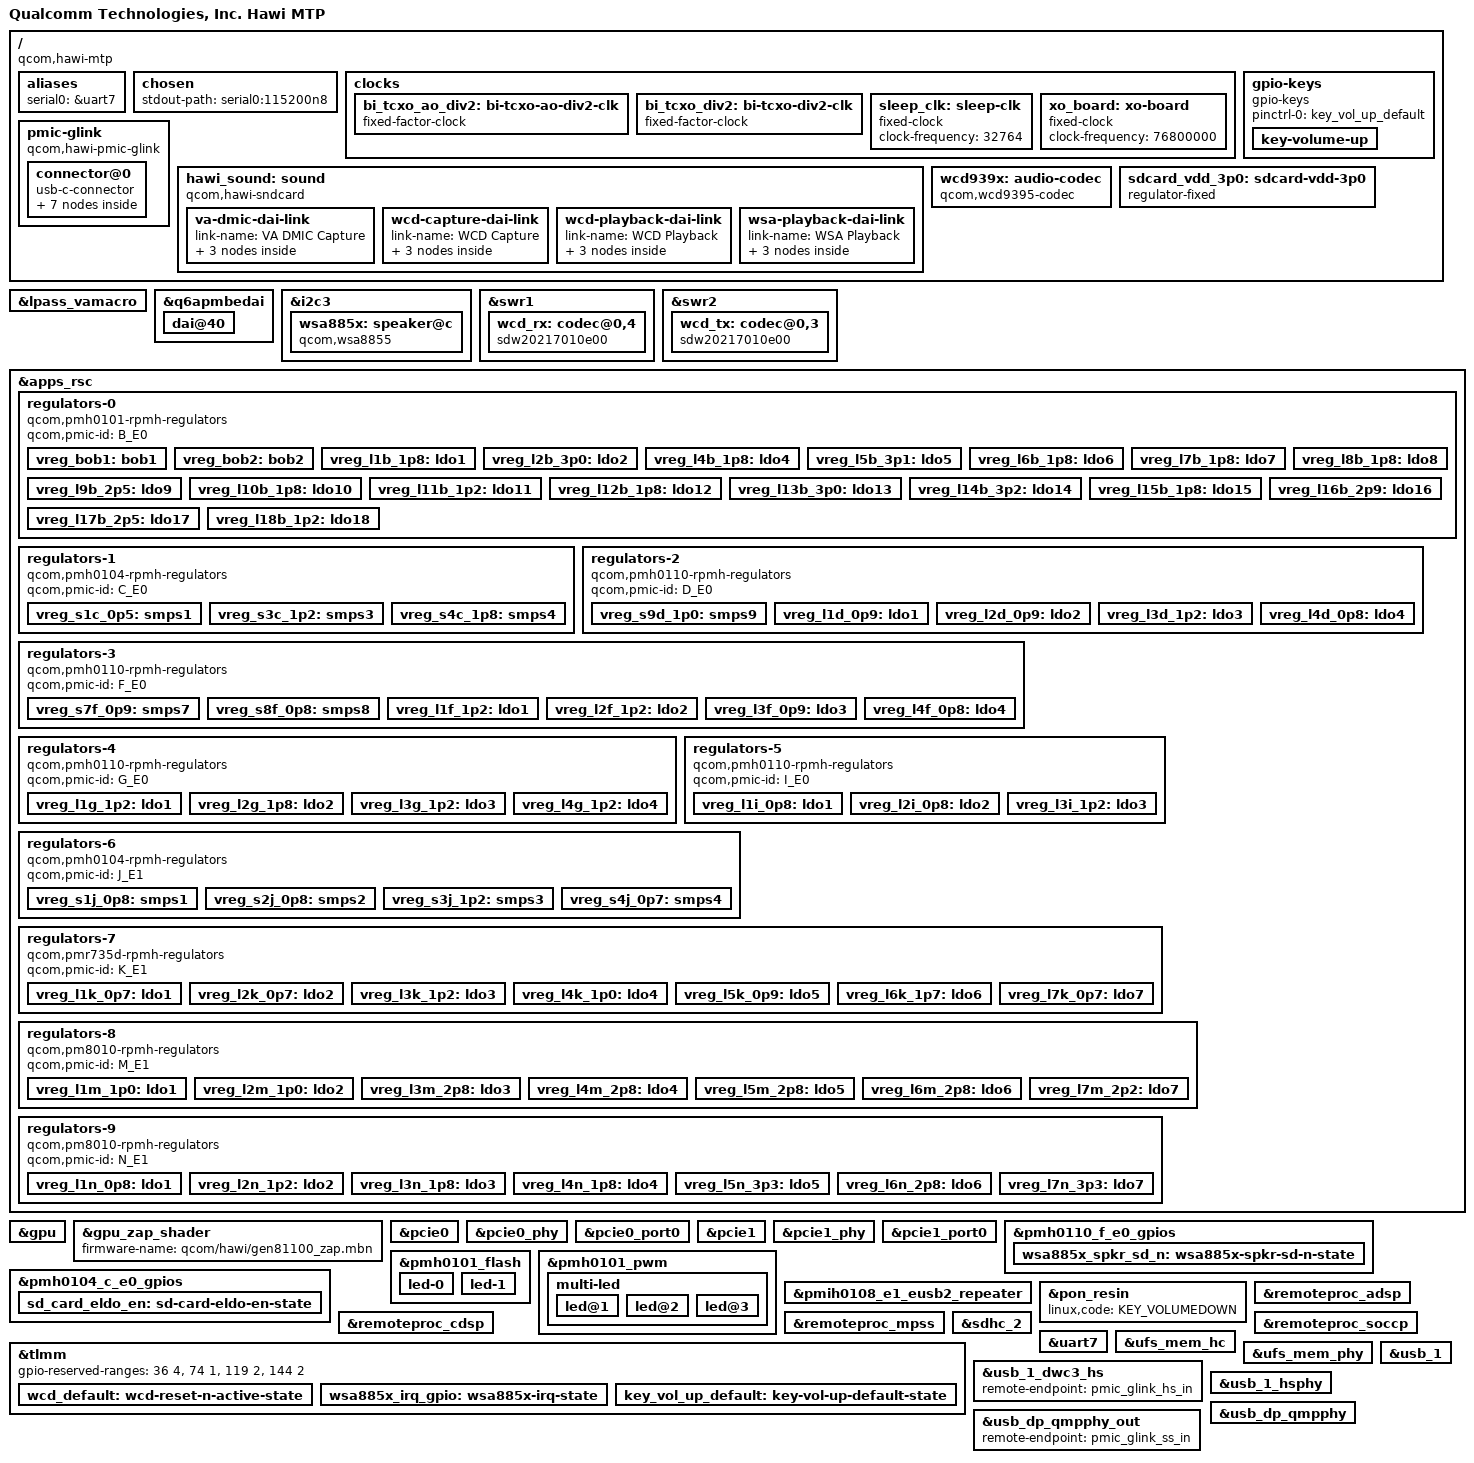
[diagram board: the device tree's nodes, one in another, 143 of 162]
// SPDX-License-Identifier: BSD-3-Clause
/*
 * Copyright (c) Qualcomm Technologies, Inc. and/or its subsidiaries.
 */

/dts-v1/;
#include <dt-bindings/gpio/gpio.h>
#include <dt-bindings/interrupt-controller/irq.h>
#include <dt-bindings/input/linux-event-codes.h>
#include <dt-bindings/leds/common.h>
#include <dt-bindings/pinctrl/qcom,pmic-gpio.h>
#include <dt-bindings/regulator/qcom,rpmh-regulator.h>
#include <dt-bindings/sound/qcom,q6dsp-lpass-ports.h>

#include "hawi.dtsi"

#include "pmd8028-kaanapali.dtsi"	/* SPMI1: SID-4 */
#include "pmh0101.dtsi"			/* SPMI0: SID-1 */
#include "pmh0104-hawi.dtsi"		/* SPMI0: SID-2 SPMI1: SID-9 */
#include "pmh0110-kaanapali.dtsi"	/* SPMI0: SID-3/5/6/8 */
#include "pmih0108-kaanapali.dtsi"	/* SPMI1: SID-7 */
#include "pmk8850.dtsi"			/* SPMI0: SID-0 */
#include "pmr735d-kaanapali.dtsi"	/* SPMI1: SID-A */
#include "pm8010-kaanapali.dtsi"	/* SPMI1: SID-C/D */

/ {
	model = "Qualcomm Technologies, Inc. Hawi MTP";
	compatible = "qcom,hawi-mtp", "qcom,hawi";
	chassis-type = "handset";

	aliases {
		serial0 = &uart7;
	};

	chosen {
		stdout-path = "serial0:115200n8";
	};

	clocks {
		bi_tcxo_ao_div2: bi-tcxo-ao-div2-clk {
			compatible = "fixed-factor-clock";
			#clock-cells = <0>;

			clocks = <&rpmhcc RPMH_CXO_CLK_A>;
			clock-mult = <1>;
			clock-div = <2>;
		};

		bi_tcxo_div2: bi-tcxo-div2-clk {
			compatible = "fixed-factor-clock";
			#clock-cells = <0>;

			clocks = <&rpmhcc RPMH_CXO_CLK>;
			clock-mult = <1>;
			clock-div = <2>;
		};

		sleep_clk: sleep-clk {
			compatible = "fixed-clock";
			clock-frequency = <32764>;
			#clock-cells = <0>;
		};

		xo_board: xo-board {
			compatible = "fixed-clock";
			clock-frequency = <76800000>;
			#clock-cells = <0>;
		};
	};

	gpio-keys {
		compatible = "gpio-keys";

		pinctrl-0 = <&key_vol_up_default>;
		pinctrl-names = "default";

		key-volume-up {
			label = "Volume Up";
			linux,code = <KEY_VOLUMEUP>;
			gpios = <&tlmm 101 GPIO_ACTIVE_LOW>;
			debounce-interval = <15>;
			linux,can-disable;
			wakeup-source;
		};
	};

	pmic-glink {
		compatible = "qcom,hawi-pmic-glink",
			     "qcom,kaanapali-pmic-glink",
			     "qcom,pmic-glink";
		#address-cells = <1>;
		#size-cells = <0>;

		connector@0 {
			compatible = "usb-c-connector";
			reg = <0>;

			power-role = "dual";
			data-role = "dual";

			ports {
				#address-cells = <1>;
				#size-cells = <0>;

				port@0 {
					reg = <0>;

					pmic_glink_hs_in: endpoint {
						remote-endpoint = <&usb_1_dwc3_hs>;
					};
				};

				port@1 {
					reg = <1>;

					pmic_glink_ss_in: endpoint {
						remote-endpoint = <&usb_dp_qmpphy_out>;
					};
				};

				port@2 {
					reg = <2>;

					pmic_glink_dp_out: endpoint {
						//remote-endpoint = <&usb_dp_qmpphy_dp_in>;
					};
				};
			};
		};
	};

	hawi_sound: sound {
		compatible = "qcom,hawi-sndcard", "qcom,sm8450-sndcard";
		model = "HAWI-MTP";

		audio-routing = "IN1_HPHL", "HPHL_OUT",
				"IN2_HPHR", "HPHR_OUT",
				"AMIC2", "MIC BIAS2",
				"VA DMIC0", "MIC BIAS1",
				"VA DMIC1", "MIC BIAS1",
				"VA DMIC2", "MIC BIAS3",
				"VA DMIC3", "MIC BIAS3",
				"TX SWR_INPUT", "ADC2_OUTPUT";

		pinctrl-names = "default", "sleep";
		pinctrl-0 = <&lpi_i2s1_active>;
		pinctrl-1 = <&lpi_i2s1_sleep>;

		va-dmic-dai-link {
			link-name = "VA DMIC Capture";

			codec {
				sound-dai = <&lpass_vamacro 0>;
			};

			cpu {
				sound-dai = <&q6apmbedai VA_CODEC_DMA_TX_0>;
			};

			platform {
				sound-dai = <&q6apm>;
			};
		};

		wcd-capture-dai-link {
			link-name = "WCD Capture";

			codec {
				sound-dai = <&wcd939x 1>, <&swr2 0>, <&lpass_txmacro 0>;
			};

			cpu {
				sound-dai = <&q6apmbedai TX_CODEC_DMA_TX_3>;
			};

			platform {
				sound-dai = <&q6apm>;
			};
		};

		wcd-playback-dai-link {
			link-name = "WCD Playback";

			codec {
				sound-dai = <&wcd939x 0>, <&swr1 0>, <&lpass_rxmacro 0>;
			};

			cpu {
				sound-dai = <&q6apmbedai RX_CODEC_DMA_RX_0>;
			};

			platform {
				sound-dai = <&q6apm>;
			};
		};

		wsa-playback-dai-link {
			link-name = "WSA Playback";

			codec {
				sound-dai = <&wsa885x>;
				dai-tdm-slot-num = <2>;
				dai-tdm-slot-width = <32>;
				dai-tdm-slot-rx-mask = <1 1>;
			};

			cpu {
				sound-dai = <&q6apmbedai AIF_TDM_RX_1>;
				dai-tdm-slot-num = <2>;
				dai-tdm-slot-width = <32>;
				dai-tdm-slot-rx-mask = <1 1>;
			};

			platform {
				sound-dai = <&q6apm>;
			};
		};
	};

	wcd939x: audio-codec {
		compatible = "qcom,wcd9395-codec", "qcom,wcd9390-codec";

		pinctrl-0 = <&wcd_default>;
		pinctrl-names = "default";

		qcom,mbhc-buttons-vthreshold-microvolt = <75000 150000 237000 500000
							 500000 500000 500000 500000>;
		qcom,mbhc-headphone-vthreshold-microvolt = <50000>;
		qcom,mbhc-headset-vthreshold-microvolt = <1700000>;
		qcom,micbias1-microvolt = <1800000>;
		qcom,micbias2-microvolt = <1800000>;
		qcom,micbias3-microvolt = <1800000>;
		qcom,micbias4-microvolt = <1800000>;
		qcom,rx-device = <&wcd_rx>;
		qcom,tx-device = <&wcd_tx>;

		reset-gpios = <&tlmm 161 GPIO_ACTIVE_LOW>;

		vdd-buck-supply = <&vreg_l15b_1p8>;
		vdd-io-supply = <&vreg_l15b_1p8>;
		vdd-mic-bias-supply = <&vreg_bob1>;
		vdd-px-supply = <&vreg_l3i_1p2>;
		vdd-rxtx-supply = <&vreg_l15b_1p8>;

		#sound-dai-cells = <1>;
	};

	sdcard_vdd_3p0: sdcard-vdd-3p0 {
		compatible = "regulator-fixed";

		regulator-name = "sdc-vdd123";
		regulator-min-microvolt = <3000000>;
		regulator-max-microvolt = <3000000>;
		regulator-enable-ramp-delay = <1500>;

		gpio = <&pmh0104_c_e0_gpios 5 GPIO_ACTIVE_HIGH>;
		enable-active-high;

		pinctrl-0 = <&sd_card_eldo_en>;
		pinctrl-names = "default";

		vin-supply = <&vreg_bob1>;
	};
};

&lpass_vamacro {
	pinctrl-0 = <&dmic01_default>, <&dmic23_default>;
	pinctrl-names = "default";

	vdd-micb-supply = <&vreg_l10b_1p8>;
	qcom,dmic-sample-rate = <4800000>;
};


&q6apmbedai {
	dai@40 {
		reg = <AIF_TDM_RX_1>;
		clocks = <&q6prmcc LPASS_CLK_ID_QAIF_IF1_IBIT
			  LPASS_CLK_ATTRIBUTE_COUPLE_NO>;
		clock-names = "bclk";
	};
};

&i2c3 {
	status = "okay";

	wsa885x: speaker@c {
		compatible = "qcom,wsa8855";
		reg = <0x0c>;

		interrupt-parent = <&tlmm>;
		interrupts = <77 IRQ_TYPE_EDGE_FALLING>;

		pinctrl-0 = <&wsa885x_spkr_sd_n &wsa885x_irq_gpio>;
		pinctrl-names = "default";

		powerdown-gpios = <&pmh0110_f_e0_gpios 11 GPIO_ACTIVE_LOW>;

		vdd-1p8-supply = <&vreg_l2g_1p8>;
		vdd-io-supply = <&vreg_l1g_1p2>;

		qcom,battery-config = "1s";

		#sound-dai-cells = <0>;

		status = "okay";
	};
};

&swr1 {
	status = "okay";
	wcd_rx: codec@0,4 {
		compatible = "sdw20217010e00";
		reg = <0 4>;

		qcom,rx-port-mapping = <1 2 3 4 5 9>;
	};
};

&swr2 {
	status = "okay";

	wcd_tx: codec@0,3 {
		compatible = "sdw20217010e00";
		reg = <0 3>;
		qcom,tx-port-mapping = <3 3 3 4>;
	};
};

&apps_rsc {
	regulators-0 {
		compatible = "qcom,pmh0101-rpmh-regulators";
		qcom,pmic-id = "B_E0";

		vreg_bob1: bob1 {
			regulator-name = "vreg_bob1";
			regulator-min-microvolt = <3008000>;
			regulator-max-microvolt = <4000000>;
			regulator-initial-mode = <RPMH_REGULATOR_MODE_HPM>;
		};

		vreg_bob2: bob2 {
			regulator-name = "vreg_bob2";
			regulator-min-microvolt = <2704000>;
			regulator-max-microvolt = <3552000>;
			regulator-initial-mode = <RPMH_REGULATOR_MODE_HPM>;
		};

		vreg_l1b_1p8: ldo1 {
			regulator-name = "vreg_l1b_1p8";
			regulator-min-microvolt = <1800000>;
			regulator-max-microvolt = <1800000>;
			regulator-initial-mode = <RPMH_REGULATOR_MODE_AUTO>;
			regulator-allow-set-load;
			regulator-allowed-modes = <RPMH_REGULATOR_MODE_LPM
						   RPMH_REGULATOR_MODE_AUTO>;
		};

		vreg_l2b_3p0: ldo2 {
			regulator-name = "vreg_l2b_3p0";
			regulator-min-microvolt = <3008000>;
			regulator-max-microvolt = <3008000>;
			regulator-initial-mode = <RPMH_REGULATOR_MODE_AUTO>;
			regulator-allow-set-load;
			regulator-allowed-modes = <RPMH_REGULATOR_MODE_LPM
						   RPMH_REGULATOR_MODE_AUTO>;
		};

		vreg_l4b_1p8: ldo4 {
			regulator-name = "vreg_l4b_1p8";
			regulator-min-microvolt = <1800000>;
			regulator-max-microvolt = <1800000>;
			regulator-initial-mode = <RPMH_REGULATOR_MODE_AUTO>;
			regulator-allow-set-load;
			regulator-allowed-modes = <RPMH_REGULATOR_MODE_LPM
						   RPMH_REGULATOR_MODE_AUTO>;
		};

		vreg_l5b_3p1: ldo5 {
			regulator-name = "vreg_l5b_3p1";
			regulator-min-microvolt = <3104000>;
			regulator-max-microvolt = <3104000>;
			regulator-initial-mode = <RPMH_REGULATOR_MODE_AUTO>;
			regulator-allow-set-load;
			regulator-allowed-modes = <RPMH_REGULATOR_MODE_LPM
						   RPMH_REGULATOR_MODE_AUTO>;
		};

		vreg_l6b_1p8: ldo6 {
			regulator-name = "vreg_l6b_1p8";
			regulator-min-microvolt = <1800000>;
			regulator-max-microvolt = <3008000>;
			regulator-initial-mode = <RPMH_REGULATOR_MODE_AUTO>;
			regulator-allow-set-load;
			regulator-allowed-modes = <RPMH_REGULATOR_MODE_LPM
						   RPMH_REGULATOR_MODE_AUTO>;
		};

		vreg_l7b_1p8: ldo7 {
			regulator-name = "vreg_l7b_1p8";
			regulator-min-microvolt = <1800000>;
			regulator-max-microvolt = <3008000>;
			regulator-initial-mode = <RPMH_REGULATOR_MODE_AUTO>;
			regulator-allow-set-load;
			regulator-allowed-modes = <RPMH_REGULATOR_MODE_LPM
						   RPMH_REGULATOR_MODE_AUTO>;
		};

		vreg_l8b_1p8: ldo8 {
			regulator-name = "vreg_l8b_1p8";
			regulator-min-microvolt = <1800000>;
			regulator-max-microvolt = <3008000>;
			regulator-initial-mode = <RPMH_REGULATOR_MODE_AUTO>;
			regulator-allow-set-load;
			regulator-allowed-modes = <RPMH_REGULATOR_MODE_LPM
						   RPMH_REGULATOR_MODE_AUTO>;
		};

		vreg_l9b_2p5: ldo9 {
			regulator-name = "vreg_l9b_2p5";
			regulator-min-microvolt = <2504000>;
			regulator-max-microvolt = <2504000>;
			regulator-initial-mode = <RPMH_REGULATOR_MODE_HPM>;
			regulator-allow-set-load;
			regulator-allowed-modes = <RPMH_REGULATOR_MODE_LPM
						   RPMH_REGULATOR_MODE_HPM>;
		};

		vreg_l10b_1p8: ldo10 {
			regulator-name = "vreg_l10b_1p8";
			regulator-min-microvolt = <1800000>;
			regulator-max-microvolt = <1800000>;
			regulator-initial-mode = <RPMH_REGULATOR_MODE_AUTO>;
			regulator-allow-set-load;
			regulator-allowed-modes = <RPMH_REGULATOR_MODE_LPM
						   RPMH_REGULATOR_MODE_AUTO>;
		};

		vreg_l11b_1p2: ldo11 {
			regulator-name = "vreg_l11b_1p2";
			regulator-min-microvolt = <1200000>;
			regulator-max-microvolt = <1200000>;
			regulator-initial-mode = <RPMH_REGULATOR_MODE_AUTO>;
			regulator-allow-set-load;
			regulator-allowed-modes = <RPMH_REGULATOR_MODE_LPM
						   RPMH_REGULATOR_MODE_AUTO>;
		};

		vreg_l12b_1p8: ldo12 {
			regulator-name = "vreg_l12b_1p8";
			regulator-min-microvolt = <1800000>;
			regulator-max-microvolt = <1800000>;
			regulator-initial-mode = <RPMH_REGULATOR_MODE_AUTO>;
			regulator-allow-set-load;
			regulator-allowed-modes = <RPMH_REGULATOR_MODE_LPM
						   RPMH_REGULATOR_MODE_AUTO>;
		};

		vreg_l13b_3p0: ldo13 {
			regulator-name = "vreg_l13b_3p0";
			regulator-min-microvolt = <3000000>;
			regulator-max-microvolt = <3000000>;
			regulator-initial-mode = <RPMH_REGULATOR_MODE_AUTO>;
			regulator-allow-set-load;
			regulator-allowed-modes = <RPMH_REGULATOR_MODE_LPM
						   RPMH_REGULATOR_MODE_AUTO>;
		};

		vreg_l14b_3p2: ldo14 {
			regulator-name = "vreg_l14b_3p2";
			regulator-min-microvolt = <3200000>;
			regulator-max-microvolt = <3200000>;
			regulator-initial-mode = <RPMH_REGULATOR_MODE_AUTO>;
			regulator-allow-set-load;
			regulator-allowed-modes = <RPMH_REGULATOR_MODE_LPM
						   RPMH_REGULATOR_MODE_AUTO>;
		};

		vreg_l15b_1p8: ldo15 {
			regulator-name = "vreg_l15b_1p8";
			regulator-min-microvolt = <1800000>;
			regulator-max-microvolt = <1800000>;
			regulator-initial-mode = <RPMH_REGULATOR_MODE_AUTO>;
			regulator-allow-set-load;
			regulator-allowed-modes = <RPMH_REGULATOR_MODE_LPM
						   RPMH_REGULATOR_MODE_AUTO>;
		};

		vreg_l16b_2p9: ldo16 {
			regulator-name = "vreg_l16b_2p9";
			regulator-min-microvolt = <1800000>;
			regulator-max-microvolt = <3600000>;
			regulator-initial-mode = <RPMH_REGULATOR_MODE_AUTO>;
			regulator-allow-set-load;
			regulator-allowed-modes = <RPMH_REGULATOR_MODE_LPM
						   RPMH_REGULATOR_MODE_AUTO>;
		};

		vreg_l17b_2p5: ldo17 {
			regulator-name = "vreg_l17b_2p5";
			regulator-min-microvolt = <2504000>;
			regulator-max-microvolt = <2504000>;
			regulator-initial-mode = <RPMH_REGULATOR_MODE_HPM>;
			regulator-allow-set-load;
			regulator-allowed-modes = <RPMH_REGULATOR_MODE_LPM
						   RPMH_REGULATOR_MODE_HPM>;
		};

		vreg_l18b_1p2: ldo18 {
			regulator-name = "vreg_l18b_1p2";
			regulator-min-microvolt = <1200000>;
			regulator-max-microvolt = <1200000>;
			regulator-initial-mode = <RPMH_REGULATOR_MODE_AUTO>;
			regulator-allow-set-load;
			regulator-allowed-modes = <RPMH_REGULATOR_MODE_LPM
						   RPMH_REGULATOR_MODE_AUTO>;
		};
	};

	regulators-1 {
		compatible = "qcom,pmh0104-rpmh-regulators";
		qcom,pmic-id = "C_E0";

		vreg_s1c_0p5: smps1 {
			regulator-name = "vreg_s1c_0p5";
			regulator-min-microvolt = <300000>;
			regulator-max-microvolt = <572000>;
			regulator-initial-mode = <RPMH_REGULATOR_MODE_HPM>;
		};

		vreg_s3c_1p2: smps3 {
			regulator-name = "vreg_s3c_1p2";
			regulator-min-microvolt = <1224000>;
			regulator-max-microvolt = <1372000>;
			regulator-initial-mode = <RPMH_REGULATOR_MODE_HPM>;
		};

		vreg_s4c_1p8: smps4 {
			regulator-name = "vreg_s4c_1p8";
			regulator-min-microvolt = <1800000>;
			regulator-max-microvolt = <2000000>;
			regulator-initial-mode = <RPMH_REGULATOR_MODE_HPM>;
		};
	};

	regulators-2 {
		compatible = "qcom,pmh0110-rpmh-regulators";
		qcom,pmic-id = "D_E0";

		vreg_s9d_1p0: smps9 {
			regulator-name = "vreg_s9d_1p0";
			regulator-min-microvolt = <900000>;
			regulator-max-microvolt = <1200000>;
			regulator-initial-mode = <RPMH_REGULATOR_MODE_HPM>;
		};

		vreg_l1d_0p9: ldo1 {
			regulator-name = "vreg_l1d_0p9";
			regulator-min-microvolt = <824000>;
			regulator-max-microvolt = <952000>;
			regulator-initial-mode = <RPMH_REGULATOR_MODE_AUTO>;
			regulator-allow-set-load;
			regulator-allowed-modes = <RPMH_REGULATOR_MODE_LPM
						   RPMH_REGULATOR_MODE_AUTO>;
		};

		vreg_l2d_0p9: ldo2 {
			regulator-name = "vreg_l2d_0p9";
			regulator-min-microvolt = <824000>;
			regulator-max-microvolt = <920000>;
			regulator-initial-mode = <RPMH_REGULATOR_MODE_AUTO>;
			regulator-allow-set-load;
			regulator-allowed-modes = <RPMH_REGULATOR_MODE_LPM
						   RPMH_REGULATOR_MODE_AUTO>;
		};

		vreg_l3d_1p2: ldo3 {
			regulator-name = "vreg_l3d_1p2";
			regulator-min-microvolt = <1200000>;
			regulator-max-microvolt = <1256000>;
			regulator-initial-mode = <RPMH_REGULATOR_MODE_AUTO>;
			regulator-allow-set-load;
			regulator-allowed-modes = <RPMH_REGULATOR_MODE_LPM
						   RPMH_REGULATOR_MODE_AUTO>;
		};

		vreg_l4d_0p8: ldo4 {
			regulator-name = "vreg_l4d_0p8";
			regulator-min-microvolt = <880000>;
			regulator-max-microvolt = <880000>;
			regulator-initial-mode = <RPMH_REGULATOR_MODE_AUTO>;
			regulator-allow-set-load;
			regulator-allowed-modes = <RPMH_REGULATOR_MODE_LPM
						   RPMH_REGULATOR_MODE_AUTO>;
		};
	};

	regulators-3 {
		compatible = "qcom,pmh0110-rpmh-regulators";
		qcom,pmic-id = "F_E0";

		vreg_s7f_0p9: smps7 {
			regulator-name = "vreg_s7f_0p9";
			regulator-min-microvolt = <900000>;
			regulator-max-microvolt = <972000>;
			regulator-initial-mode = <RPMH_REGULATOR_MODE_HPM>;
		};

		vreg_s8f_0p8: smps8 {
			regulator-name = "vreg_s8f_0p8";
			regulator-min-microvolt = <880000>;
			regulator-max-microvolt = <1100000>;
			regulator-initial-mode = <RPMH_REGULATOR_MODE_HPM>;
		};

		vreg_l1f_1p2: ldo1 {
			regulator-name = "vreg_l1f_1p2";
			regulator-min-microvolt = <744000>;
			regulator-max-microvolt = <1200000>;
			regulator-initial-mode = <RPMH_REGULATOR_MODE_AUTO>;
			regulator-allow-set-load;
			regulator-allowed-modes = <RPMH_REGULATOR_MODE_LPM
						   RPMH_REGULATOR_MODE_AUTO>;
		};

		vreg_l2f_1p2: ldo2 {
			regulator-name = "vreg_l2f_1p2";
			regulator-min-microvolt = <1200000>;
			regulator-max-microvolt = <1200000>;
			regulator-initial-mode = <RPMH_REGULATOR_MODE_AUTO>;
			regulator-allow-set-load;
			regulator-allowed-modes = <RPMH_REGULATOR_MODE_LPM
						   RPMH_REGULATOR_MODE_AUTO>;
		};

		vreg_l3f_0p9: ldo3 {
			regulator-name = "vreg_l3f_0p9";
			regulator-min-microvolt = <912000>;
			regulator-max-microvolt = <912000>;
			regulator-initial-mode = <RPMH_REGULATOR_MODE_AUTO>;
			regulator-allow-set-load;
			regulator-allowed-modes = <RPMH_REGULATOR_MODE_LPM
						   RPMH_REGULATOR_MODE_AUTO>;
		};

		vreg_l4f_0p8: ldo4 {
			regulator-name = "vreg_l4f_0p8";
			regulator-min-microvolt = <880000>;
			regulator-max-microvolt = <912000>;
			regulator-initial-mode = <RPMH_REGULATOR_MODE_AUTO>;
			regulator-allow-set-load;
			regulator-allowed-modes = <RPMH_REGULATOR_MODE_LPM
						   RPMH_REGULATOR_MODE_AUTO>;
		};
	};

	regulators-4 {
		compatible = "qcom,pmh0110-rpmh-regulators";
		qcom,pmic-id = "G_E0";

		vreg_l1g_1p2: ldo1 {
			regulator-name = "vreg_l1g_1p2";
			regulator-min-microvolt = <1200000>;
			regulator-max-microvolt = <1200000>;
			regulator-initial-mode = <RPMH_REGULATOR_MODE_AUTO>;
			regulator-allow-set-load;
			regulator-allowed-modes = <RPMH_REGULATOR_MODE_LPM
						   RPMH_REGULATOR_MODE_AUTO>;
		};

		vreg_l2g_1p8: ldo2 {
			regulator-name = "vreg_l2g_1p8";
			regulator-min-microvolt = <1800000>;
			regulator-max-microvolt = <1800000>;
			regulator-initial-mode = <RPMH_REGULATOR_MODE_AUTO>;
			regulator-allow-set-load;
			regulator-allowed-modes = <RPMH_REGULATOR_MODE_LPM
						   RPMH_REGULATOR_MODE_AUTO>;
		};

		vreg_l3g_1p2: ldo3 {
			regulator-name = "vreg_l3g_1p2";
			regulator-min-microvolt = <1200000>;
			regulator-max-microvolt = <1200000>;
			regulator-initial-mode = <RPMH_REGULATOR_MODE_AUTO>;
			regulator-allow-set-load;
			regulator-allowed-modes = <RPMH_REGULATOR_MODE_LPM
						   RPMH_REGULATOR_MODE_AUTO>;
		};

		vreg_l4g_1p2: ldo4 {
			regulator-name = "vreg_l4g_1p2";
			regulator-min-microvolt = <1200000>;
			regulator-max-microvolt = <1200000>;
			regulator-initial-mode = <RPMH_REGULATOR_MODE_AUTO>;
			regulator-allow-set-load;
			regulator-allowed-modes = <RPMH_REGULATOR_MODE_LPM
						   RPMH_REGULATOR_MODE_AUTO>;
		};
	};

	regulators-5 {
		compatible = "qcom,pmh0110-rpmh-regulators";
		qcom,pmic-id = "I_E0";

		vreg_l1i_0p8: ldo1 {
			regulator-name = "vreg_l1i_0p8";
			regulator-min-microvolt = <880000>;
			regulator-max-microvolt = <920000>;
			regulator-initial-mode = <RPMH_REGULATOR_MODE_AUTO>;
			regulator-allow-set-load;
			regulator-allowed-modes = <RPMH_REGULATOR_MODE_LPM
						   RPMH_REGULATOR_MODE_AUTO>;
		};

		vreg_l2i_0p8: ldo2 {
			regulator-name = "vreg_l2i_0p8";
			regulator-min-microvolt = <880000>;
			regulator-max-microvolt = <1104000>;
			regulator-initial-mode = <RPMH_REGULATOR_MODE_AUTO>;
			regulator-allow-set-load;
			regulator-allowed-modes = <RPMH_REGULATOR_MODE_LPM
						   RPMH_REGULATOR_MODE_AUTO>;
		};

		vreg_l3i_1p2: ldo3 {
			regulator-name = "vreg_l3i_1p2";
			regulator-min-microvolt = <1200000>;
			regulator-max-microvolt = <1304000>;
			regulator-initial-mode = <RPMH_REGULATOR_MODE_AUTO>;
			regulator-allow-set-load;
			regulator-allowed-modes = <RPMH_REGULATOR_MODE_LPM
						   RPMH_REGULATOR_MODE_AUTO>;
		};
	};

	regulators-6 {
		compatible = "qcom,pmh0104-rpmh-regulators";
		qcom,pmic-id = "J_E1";

		vreg_s1j_0p8: smps1 {
			regulator-name = "vreg_s1j_0p8";
			regulator-min-microvolt = <400000>;
			regulator-max-microvolt = <1000000>;
			regulator-initial-mode = <RPMH_REGULATOR_MODE_HPM>;
		};

		vreg_s2j_0p8: smps2 {
			regulator-name = "vreg_s2j_0p8";
			regulator-min-microvolt = <400000>;
			regulator-max-microvolt = <1100000>;
			regulator-initial-mode = <RPMH_REGULATOR_MODE_HPM>;
		};

		vreg_s3j_1p2: smps3 {
			regulator-name = "vreg_s3j_1p2";
			regulator-min-microvolt = <1200000>;
			regulator-max-microvolt = <1300000>;
			regulator-initial-mode = <RPMH_REGULATOR_MODE_HPM>;
		};

		vreg_s4j_0p7: smps4 {
			regulator-name = "vreg_s4j_0p7";
			regulator-min-microvolt = <300000>;
			regulator-max-microvolt = <1000000>;
			regulator-initial-mode = <RPMH_REGULATOR_MODE_HPM>;
		};
	};

	regulators-7 {
		compatible = "qcom,pmr735d-rpmh-regulators";
		qcom,pmic-id = "K_E1";

		vreg_l1k_0p7: ldo1 {
			regulator-name = "vreg_l1k_0p7";
			regulator-min-microvolt = <496000>;
			regulator-max-microvolt = <1104000>;
			regulator-initial-mode = <RPMH_REGULATOR_MODE_HPM>;
			regulator-allow-set-load;
			regulator-allowed-modes = <RPMH_REGULATOR_MODE_LPM
						   RPMH_REGULATOR_MODE_HPM>;
		};

		vreg_l2k_0p7: ldo2 {
			regulator-name = "vreg_l2k_0p7";
			regulator-min-microvolt = <696000>;
			regulator-max-microvolt = <1000000>;
			regulator-initial-mode = <RPMH_REGULATOR_MODE_HPM>;
			regulator-allow-set-load;
			regulator-allowed-modes = <RPMH_REGULATOR_MODE_LPM
						   RPMH_REGULATOR_MODE_HPM>;
		};

		vreg_l3k_1p2: ldo3 {
			regulator-name = "vreg_l3k_1p2";
			regulator-min-microvolt = <1200000>;
			regulator-max-microvolt = <1256000>;
			regulator-initial-mode = <RPMH_REGULATOR_MODE_HPM>;
			regulator-allow-set-load;
			regulator-allowed-modes = <RPMH_REGULATOR_MODE_LPM
						   RPMH_REGULATOR_MODE_HPM>;
		};

		vreg_l4k_1p0: ldo4 {
			regulator-name = "vreg_l4k_1p0";
			regulator-min-microvolt = <1000000>;
			regulator-max-microvolt = <1200000>;
			regulator-initial-mode = <RPMH_REGULATOR_MODE_HPM>;
			regulator-allow-set-load;
			regulator-allowed-modes = <RPMH_REGULATOR_MODE_LPM
						   RPMH_REGULATOR_MODE_HPM>;
		};

		vreg_l5k_0p9: ldo5 {
			regulator-name = "vreg_l5k_0p9";
			regulator-min-microvolt = <696000>;
			regulator-max-microvolt = <1000000>;
			regulator-initial-mode = <RPMH_REGULATOR_MODE_HPM>;
			regulator-allow-set-load;
			regulator-allowed-modes = <RPMH_REGULATOR_MODE_LPM
						   RPMH_REGULATOR_MODE_HPM>;
		};

		vreg_l6k_1p7: ldo6 {
			regulator-name = "vreg_l6k_1p7";
			regulator-min-microvolt = <1696000>;
			regulator-max-microvolt = <2000000>;
			regulator-initial-mode = <RPMH_REGULATOR_MODE_HPM>;
			regulator-allow-set-load;
			regulator-allowed-modes = <RPMH_REGULATOR_MODE_LPM
						   RPMH_REGULATOR_MODE_HPM>;
		};

		vreg_l7k_0p7: ldo7 {
			regulator-name = "vreg_l7k_0p7";
			regulator-min-microvolt = <696000>;
			regulator-max-microvolt = <848000>;
			regulator-initial-mode = <RPMH_REGULATOR_MODE_HPM>;
			regulator-allow-set-load;
			regulator-allowed-modes = <RPMH_REGULATOR_MODE_LPM
						   RPMH_REGULATOR_MODE_HPM>;
		};
	};

	regulators-8 {
		compatible = "qcom,pm8010-rpmh-regulators";
		qcom,pmic-id = "M_E1";

		vreg_l1m_1p0: ldo1 {
			regulator-name = "vreg_l1m_1p0";
			regulator-min-microvolt = <1000000>;
			regulator-max-microvolt = <1056000>;
			regulator-initial-mode = <RPMH_REGULATOR_MODE_HPM>;
			regulator-allow-set-load;
			regulator-allowed-modes = <RPMH_REGULATOR_MODE_LPM
						   RPMH_REGULATOR_MODE_HPM>;
		};

		vreg_l2m_1p0: ldo2 {
			regulator-name = "vreg_l2m_1p0";
			regulator-min-microvolt = <1096000>;
			regulator-max-microvolt = <1104000>;
			regulator-initial-mode = <RPMH_REGULATOR_MODE_HPM>;
			regulator-allow-set-load;
			regulator-allowed-modes = <RPMH_REGULATOR_MODE_LPM
						   RPMH_REGULATOR_MODE_HPM>;
		};

		vreg_l3m_2p8: ldo3 {
			regulator-name = "vreg_l3m_2p8";
			regulator-min-microvolt = <2800000>;
			regulator-max-microvolt = <2900000>;
			regulator-initial-mode = <RPMH_REGULATOR_MODE_HPM>;
		};

		vreg_l4m_2p8: ldo4 {
			regulator-name = "vreg_l4m_2p8";
			regulator-min-microvolt = <2800000>;
			regulator-max-microvolt = <2896000>;
			regulator-initial-mode = <RPMH_REGULATOR_MODE_HPM>;
		};

		vreg_l5m_2p8: ldo5 {
			regulator-name = "vreg_l5m_2p8";
			regulator-min-microvolt = <2800000>;
			regulator-max-microvolt = <2896000>;
			regulator-initial-mode = <RPMH_REGULATOR_MODE_HPM>;
		};

		vreg_l6m_2p8: ldo6 {
			regulator-name = "vreg_l6m_2p8";
			regulator-min-microvolt = <2800000>;
			regulator-max-microvolt = <2896000>;
			regulator-initial-mode = <RPMH_REGULATOR_MODE_HPM>;
		};

		vreg_l7m_2p2: ldo7 {
			regulator-name = "vreg_l7m_2p2";
			regulator-min-microvolt = <2200000>;
			regulator-max-microvolt = <2296000>;
			regulator-initial-mode = <RPMH_REGULATOR_MODE_HPM>;
		};
	};

	regulators-9 {
		compatible = "qcom,pm8010-rpmh-regulators";
		qcom,pmic-id = "N_E1";

		vreg_l1n_0p8: ldo1 {
			regulator-name = "vreg_l1n_0p8";
			regulator-min-microvolt = <720000>;
			regulator-max-microvolt = <896000>;
			regulator-initial-mode = <RPMH_REGULATOR_MODE_HPM>;
			regulator-allow-set-load;
			regulator-allowed-modes = <RPMH_REGULATOR_MODE_LPM
						   RPMH_REGULATOR_MODE_HPM>;
		};

		vreg_l2n_1p2: ldo2 {
			regulator-name = "vreg_l2n_1p2";
			regulator-min-microvolt = <1200000>;
			regulator-max-microvolt = <1200000>;
			regulator-initial-mode = <RPMH_REGULATOR_MODE_HPM>;
			regulator-allow-set-load;
			regulator-allowed-modes = <RPMH_REGULATOR_MODE_LPM
						   RPMH_REGULATOR_MODE_HPM>;
		};

		vreg_l3n_1p8: ldo3 {
			regulator-name = "vreg_l3n_1p8";
			regulator-min-microvolt = <1800000>;
			regulator-max-microvolt = <1800000>;
			regulator-initial-mode = <RPMH_REGULATOR_MODE_HPM>;
		};

		vreg_l4n_1p8: ldo4 {
			regulator-name = "vreg_l4n_1p8";
			regulator-min-microvolt = <1800000>;
			regulator-max-microvolt = <1800000>;
			regulator-initial-mode = <RPMH_REGULATOR_MODE_HPM>;
		};

		vreg_l5n_3p3: ldo5 {
			regulator-name = "vreg_l5n_3p3";
			regulator-min-microvolt = <3296000>;
			regulator-max-microvolt = <3304000>;
			regulator-initial-mode = <RPMH_REGULATOR_MODE_HPM>;
		};

		vreg_l6n_2p8: ldo6 {
			regulator-name = "vreg_l6n_2p8";
			regulator-min-microvolt = <2800000>;
			regulator-max-microvolt = <2800000>;
			regulator-initial-mode = <RPMH_REGULATOR_MODE_HPM>;
		};

		vreg_l7n_3p3: ldo7 {
			regulator-name = "vreg_l7n_3p3";
			regulator-min-microvolt = <3296000>;
			regulator-max-microvolt = <3304000>;
			regulator-initial-mode = <RPMH_REGULATOR_MODE_HPM>;
		};
	};
};

&gpu {
	status = "okay";
};

&gpu_zap_shader {
	firmware-name = "qcom/hawi/gen81100_zap.mbn";
};

&pcie0 {
	status = "okay";
};

&pcie0_phy {
	vdda-phy-supply = <&vreg_l1i_0p8>;
	vdda-pll-supply = <&vreg_l3d_1p2>;

	status = "okay";
};

&pcie0_port0 {
	wake-gpios = <&tlmm 104 GPIO_ACTIVE_LOW>;
	reset-gpios = <&tlmm 102 GPIO_ACTIVE_LOW>;
};

&pcie1 {
	status = "okay";
};

&pcie1_phy {
	vdda-phy-supply = <&vreg_l1i_0p8>;
	vdda-pll-supply = <&vreg_l3d_1p2>;

	status = "okay";
};

&pcie1_port0 {
	wake-gpios = <&tlmm 222 GPIO_ACTIVE_LOW>;
	reset-gpios = <&tlmm 220 GPIO_ACTIVE_LOW>;
};

&pmh0110_f_e0_gpios {
	wsa885x_spkr_sd_n: wsa885x-spkr-sd-n-state {
		pins = "gpio11";
		function = "normal";
		input-disable;
		output-enable;
		power-source = <1>; /* 1.8V */
	};
};

&pmh0101_flash {
	status = "okay";

	led-0 {
		function = LED_FUNCTION_FLASH;
		function-enumerator = <0>;
		color = <LED_COLOR_ID_YELLOW>;
		led-sources = <1>, <4>;
		led-max-microamp = <500000>;
		flash-max-microamp = <2000000>;
		flash-max-timeout-us = <1280000>;
	};

	led-1 {
		function = LED_FUNCTION_FLASH;
		function-enumerator = <1>;
		color = <LED_COLOR_ID_WHITE>;
		led-sources = <2>, <3>;
		led-max-microamp = <500000>;
		flash-max-microamp = <2000000>;
		flash-max-timeout-us = <1280000>;
	};
};

&pmh0101_pwm {
	status = "okay";

	multi-led {
		color = <LED_COLOR_ID_RGB>;
		function = LED_FUNCTION_STATUS;

		#address-cells = <1>;
		#size-cells = <0>;

		led@1 {
			reg = <1>;
			color = <LED_COLOR_ID_RED>;
		};

		led@2 {
			reg = <2>;
			color = <LED_COLOR_ID_GREEN>;
		};

		led@3 {
			reg = <3>;
			color = <LED_COLOR_ID_BLUE>;
		};
	};
};

&pmh0104_c_e0_gpios {
	sd_card_eldo_en: sd-card-eldo-en-state {
		pins = "gpio5";
		function = "normal";
		input-disable;
		output-low;
		power-source = <0>;
		qcom,drive-strength = <PMIC_GPIO_STRENGTH_HIGH>;
	};
};

&pmih0108_e1_eusb2_repeater {
	vdd18-supply = <&vreg_l15b_1p8>;
	vdd3-supply = <&vreg_l5b_3p1>;
};

&pon_resin {
	linux,code = <KEY_VOLUMEDOWN>;

	status = "okay";
};

&remoteproc_adsp {
	firmware-name = "qcom/hawi/adsp.mbn",
			"qcom/hawi/adsp_dtb.mbn";

	status = "okay";
};

&remoteproc_cdsp {
	firmware-name = "qcom/hawi/cdsp.mbn",
			"qcom/hawi/cdsp_dtb.mbn";

	status = "okay";
};

&remoteproc_mpss {
	firmware-name = "qcom/hawi/modem.mbn",
			"qcom/hawi/modem_dtb.mbn";

	status = "okay";
};

&remoteproc_soccp {
	firmware-name = "qcom/hawi/soccp.mbn",
			"qcom/hawi/soccp_dtb.mbn";

	status = "okay";
};

&sdhc_2 {
	cd-gpios = <&tlmm 55 GPIO_ACTIVE_LOW>;

	vmmc-supply = <&sdcard_vdd_3p0>;
	vqmmc-supply = <&vreg_l16b_2p9>;

	bus-width = <4>;
	no-sdio;
	no-mmc;

	pinctrl-0 = <&sdc2_default>;
	pinctrl-1 = <&sdc2_sleep>;
	pinctrl-names = "default", "sleep";

	status = "okay";
};

&tlmm {
	gpio-reserved-ranges = <36 4>, /* NFC eSE SPI */
			       <74 1>, /* eSE */
			       <119 2>, /* SoCCP */
			       <144 2>; /* CXM UART */

	wcd_default: wcd-reset-n-active-state {
		pins = "gpio161";
		function = "gpio";
		drive-strength = <16>;
		bias-disable;
	};

	wsa885x_irq_gpio: wsa885x-irq-state {
		pins = "gpio77";
		function = "gpio";
		drive-strength = <2>;
		bias-disable;
	};

	key_vol_up_default: key-vol-up-default-state {
		pins = "gpio101";
		function = "gpio";
		output-disable;
		bias-pull-up;
	};
};

&uart7 {
	status = "okay";
};

&ufs_mem_hc {
	reset-gpios = <&tlmm 226 GPIO_ACTIVE_LOW>;

	vcc-supply = <&vreg_l9b_2p5>;
	vcc-max-microamp = <1200000>;

	vccq-supply = <&vreg_l4g_1p2>;
	vccq-max-microamp = <1200000>;

	status = "okay";
};

&ufs_mem_phy {
	vdda-phy-supply = <&vreg_l3f_0p9>;
	vdda-pll-supply = <&vreg_l3d_1p2>;

	status = "okay";
};

&usb_1 {
	dr_mode = "otg";
	usb-role-switch;

	status = "okay";
};

&usb_1_dwc3_hs {
	remote-endpoint = <&pmic_glink_hs_in>;
};

&usb_1_hsphy {
	vdd-supply = <&vreg_l4f_0p8>;
	vdda12-supply = <&vreg_l3d_1p2>;

	phys = <&pmih0108_e1_eusb2_repeater>;

	status = "okay";
};

&usb_dp_qmpphy {
	vdda-phy-supply = <&vreg_l4f_0p8>;
	vdda-pll-supply = <&vreg_l3d_1p2>;

	status = "okay";
};

&usb_dp_qmpphy_out {
	remote-endpoint = <&pmic_glink_ss_in>;
};
